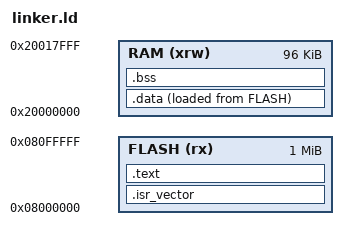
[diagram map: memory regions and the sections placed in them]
ENTRY(Reset_Handler)

_estack = ORIGIN(RAM) + LENGTH(RAM);

MEMORY
{
    FLASH (rx)  : ORIGIN = 0x08000000, LENGTH = 1024K
    RAM   (xrw) : ORIGIN = 0x20000000, LENGTH = 96K
}

SECTIONS
{
    .isr_vector :
    {
        KEEP(*(.isr_vector))
    } > FLASH

    .text :
    {
        *(.text*)
        *(.rodata*)
        . = ALIGN(4);
    } > FLASH

    .data :
    {
        _sdata = .;
        *(.data*)
        _edata = .;
    } > RAM AT > FLASH

    _sidata = LOADADDR(.data);

    .bss :
    {
        _sbss = .;
        *(.bss*)
        *(COMMON)
        _ebss = .;
    } > RAM
}
